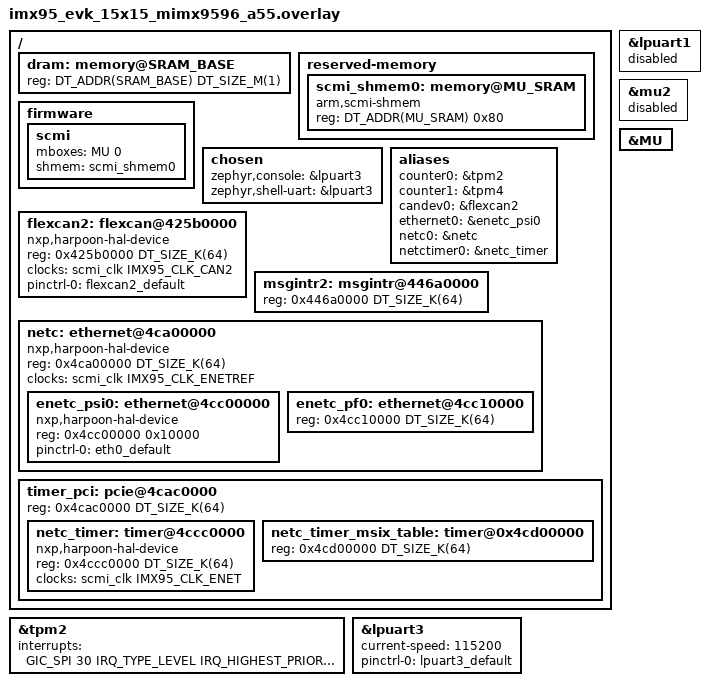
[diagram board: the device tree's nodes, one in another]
/*
 * Copyright 2024-2025 NXP
 *
 * SPDX-License-Identifier: BSD-3-Clause
 */

#define IRQ_HIGHEST_PRIORITY	0

#define SRAM_BASE	f0000000
#define MU		mu3
#define MU_SRAM		445d1000

/delete-node/ &dram;
/delete-node/ &scmi_shmem0;

/ {
	dram: memory@SRAM_BASE {
		reg = <DT_ADDR(SRAM_BASE) DT_SIZE_M(1)>;
	};

	reserved-memory {
		#address-cells = <1>;
		#size-cells = <1>;

		scmi_shmem0: memory@MU_SRAM {
			compatible = "arm,scmi-shmem";
			reg = <DT_ADDR(MU_SRAM) 0x80>;
		};
	};

	firmware {
		scmi {
			mboxes = <&MU 0>;
			shmem = <&scmi_shmem0>;
		};
	};

	chosen {
		zephyr,console = &lpuart3;
		zephyr,shell-uart = &lpuart3;
	};

	aliases {
		counter0 = &tpm2;
		counter1 = &tpm4;
		candev0 = &flexcan2;
		ethernet0 = &enetc_psi0;
		netc0 = &netc;
		netctimer0 = &netc_timer;
	};

	flexcan2: flexcan@425b0000 {
		compatible = "nxp,harpoon-hal-device";
		reg = <0x425b0000 DT_SIZE_K(64)>;
		clocks = <&scmi_clk IMX95_CLK_CAN2>;
		pinctrl-0 = <&flexcan2_default>;
		pinctrl-names = "default";
	};

	msgintr2: msgintr@446a0000 {
		reg = <0x446a0000 DT_SIZE_K(64)>;
	};

	netc: ethernet@4ca00000 {
		compatible = "nxp,harpoon-hal-device";
		reg = <0x4ca00000 DT_SIZE_K(64)>;
		clocks = <&scmi_clk IMX95_CLK_ENETREF>;
		#address-cells = <1>;
		#size-cells = <1>;

		enetc_psi0: ethernet@4cc00000 {
			compatible = "nxp,harpoon-hal-device";
			reg = <0x4cc00000 0x10000>;
			pinctrl-0 = <&eth0_default>;
			pinctrl-names = "default";
		};

		enetc_pf0: ethernet@4cc10000 {
			reg = <0x4cc10000 DT_SIZE_K(64)>;
		};
	};

	timer_pci: pcie@4cac0000 {
		reg = <0x4cac0000 DT_SIZE_K(64)>;
		#address-cells = <1>;
		#size-cells = <1>;

		netc_timer: timer@4ccc0000 {
			compatible = "nxp,harpoon-hal-device";
			reg = <0x4ccc0000 DT_SIZE_K(64)>;
			clocks = <&scmi_clk IMX95_CLK_ENET>;
		};

		netc_timer_msix_table: timer@0x4cd00000 {
			reg = <0x4cd00000 DT_SIZE_K(64)>;
		};
	};
};

&tpm2 {
	interrupts = <GIC_SPI 30 IRQ_TYPE_LEVEL
		IRQ_HIGHEST_PRIORITY>;
	status = "okay";
};

&lpuart1 {
	status = "disabled";
};

&lpuart3 {
	status = "okay";
	current-speed = <115200>;
	pinctrl-0 = <&lpuart3_default>;
	pinctrl-names = "default";
};

&mu2 {
	status = "disabled";
};

&MU {
	status = "okay";
};
